# NVIC Register Definitions: IP-XACT component
VLNV meklort:<PROJECT>:NVIC Register Definitions:1.0

## Address spaces and blocks
NVIC.NVIC: base 0xE000E000, range , width , register

## Registers
Registers are 32-bit, read-write, no defined reset value unless marked. A register's access mark holds for its fields unless they carry their own. Offsets are from the block's base; lines under a group give offsets from that group; [hi:lo] are bit positions; {n}, {i} and the like mark numbered series; 'fields as' and 'values as' point back to an identical list; <NAME> marks a mode.

## NVIC.NVIC — Nested Vectored Interrupt Controller
Base 0xE000E000
0x04 Interrupt Control Type access not given — Read the Interrupt Controller Type Register to see the number of interrupt lines that the NVIC supports.
  [3:0] INTLINESNUM
    0=0 to 32; 1=33 to 64; 2=65 to 96
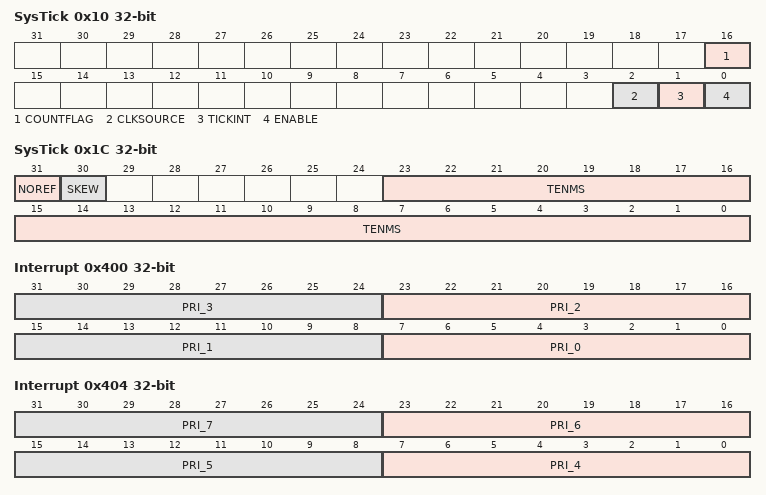
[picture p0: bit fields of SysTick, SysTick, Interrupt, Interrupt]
0x10 SysTick Control and Status — Use the SysTick Control and Status Register to enable the SysTick features.
  [16] COUNTFLAG — Returns 1 if timer counted to 0 since last time this was read. Clears on read by application of any part of the SysTick Control and Status Register. If read by the debugger using the DAP, this bit is cleared on read-only if the MasterType bit in the AHB-AP Control Register is set to 0. Otherwise, the COUNTFLAG bit is not changed by the debugger read.
  [2] CLKSOURCE — If no reference clock is provided, it is held at 1 and so gives the same time as the core clock. The core clock must be at least 2.5 times faster than the reference clock. If it is not, the count values are Unpredictable.
  [1] TICKINT — If set, counting down to 0 pends the SysTick handler.
  [0] ENABLE — It set, counter loads with the Reload value and then begins counting down. On reaching 0, it sets the COUNTFLAG to 1 and optionally pends the SysTick handler, based on TICKINT. It then loads the Reload value again, and begins counting.
0x14 SysTick Reload Value — Use the SysTick Reload Value Register to specify the start value to load into the current value register when the counter reaches 0. It can be any value between 1 and 0x00FFFFFF. A start value of 0 is possible, but has no effect because the SysTick interrupt and COUNTFLAG are activated when counting from 1 to 0.
  [23:0] RELOAD — Value to load into the SysTick Current Value Register when the counter reaches 0.
0x18 SysTick Current Value — Use the SysTick Current Value Register to find the current value in the register.
  [23:0] CURRENT — Current value at the time the register is accessed. No read-modify-write protection is provided, so change with care. This register is write-clear. Writing to it with any value clears the register to 0. Clearing this register also clears the COUNTFLAG bit of the SysTick Control and Status Register.
0x1C SysTick Calibration Value — Use the SysTick Calibration Value Register to enable software to scale to any required speed using divide and multiply.
  [31] NOREF — 1 = the reference clock is not provided.
  [30] SKEW — 1 = the calibration value is not exactly 10ms because of clock frequency. This could affect its suitability as a software real time clock.
  [23:0] TENMS — This value is the Reload value to use for 10ms timing. Depending on the value of SKEW, this might be exactly 10ms or might be the closest value. If this reads as 0, then the calibration value is not known. This is probably because the reference clock is an unknown input from the system or scalable dynamically.
0x100 Interrupt Set-Enable — Each bit in the register corresponds to one of 32 interrupts. Setting a bit in the Interrupt Set-Enable Register enables the corresponding interrupt. When the enable bit of a pending interrupt is set, the processor activates the interrupt based on its priority. When the enable bit is clear, asserting its interrupt signal pends the interrupt, but it is not possible to activate the interrupt, regardless of its priority. Therefore, a disabled interrupt can serve as a latched general-purpose I/O bit. You can read it and clear it without invoking an interrupt.
  [31:0] SETENA — Writing 0 to a SETENA bit has no effect. Reading the bit returns its current enable state. Reset clears the SETENA fields.
    0x100=H2B; 0x800=RX Packet Even (Port 0 or 2 received a packet.); 0x4000=SMBUS 0; 0x10000=SMBUS 1; 0x20000=RMU Egress (A packet was transmitted via the RMU); 0x100000=General Reset; 0x1000000=VMain (The Vmain port state has changed.); 0x2000000=Link State Even (Port 0 or 2 has had a link state event.); 0x4000000=Link State Odd (Port 1 or 3 has had a link state event.); 0x8000000=RX Packet Odd (Port 1 or 3 received a packet.)
0x180 Interrupt Clear-Enable — Each bit in the register corresponds to one of the 32 interrupts. Setting an Interrupt Clear-Enable Register bit disables the corresponding interrupt.
  [31:0] CLRENA — Writing 0 to a CLRENA bit has no effect. Reading the bit returns its current enable state.
    0x100=H2B; 0x800=RX Packet Even (Port 0 or 2 received a packet.); 0x4000=SMBUS 0; 0x10000=SMBUS 1; 0x20000=RMU Egress (A packet was transmitted via the RMU); 0x100000=General Reset; 0x1000000=VMain (The Vmain port state has changed.); 0x2000000=Link State Even (Port 0 or 2 has had a link state event.); 0x4000000=Link State Odd (Port 1 or 3 has had a link state event.); 0x8000000=RX Packet Odd (Port 1 or 3 received a packet.)
0x200 Interrupt Set-Pending — Each bit in the register corresponds to one of the 32 interrupts. Setting an Interrupt Set-Pending Register bit pends the corresponding interrupt.
  [31:0] SETPEND — Writing 0 to a SETPEND bit has no effect. Reading the bit returns its current state.
    0x100=H2B; 0x800=RX Packet Even (Port 0 or 2 received a packet.); 0x4000=SMBUS 0; 0x10000=SMBUS 1; 0x20000=RMU Egress (A packet was transmitted via the RMU); 0x100000=General Reset; 0x1000000=VMain (The Vmain port state has changed.); 0x2000000=Link State Even (Port 0 or 2 has had a link state event.); 0x4000000=Link State Odd (Port 1 or 3 has had a link state event.); 0x8000000=RX Packet Odd (Port 1 or 3 received a packet.)
0x280 Interrupt Clear-Pending — Each bit in the register corresponds to one of the 32 interrupts. Setting an Interrupt Clear-Pending Register bit puts the corresponding pending interrupt in the inactive state.
  [31:0] CLRPEND — Writing 0 to a CLRPEND bit has no effect. Reading the bit returns its current state.
    0x100=H2B; 0x800=RX Packet Even (Port 0 or 2 received a packet.); 0x4000=SMBUS 0; 0x10000=SMBUS 1; 0x20000=RMU Egress (A packet was transmitted via the RMU); 0x100000=General Reset; 0x1000000=VMain (The Vmain port state has changed.); 0x2000000=Link State Even (Port 0 or 2 has had a link state event.); 0x4000000=Link State Odd (Port 1 or 3 has had a link state event.); 0x8000000=RX Packet Odd (Port 1 or 3 received a packet.)
0x300 Active Bit — Read the Active Bit Register to determine which interrupts are active. Each flag in the register corresponds to one of the 32 interrupts.
  [31:0] ACTIVE — Interrupt active flags.
0x400 Interrupt Priority 0 — Use the Interrupt Priority Registers to assign a priority from 0 to 255 to each of the available interrupts. 0 is the highest priority, and 255 is the lowest.
  [8n+7:8n] PRI_{n} (n=0..3) — Priority of Interrupt {n}.
0x404 Interrupt Priority 1 — Use the Interrupt Priority Registers to assign a priority from 0 to 255 to each of the available interrupts. 0 is the highest priority, and 255 is the lowest.
  [8n-25:8n-32] PRI_{n} (n=4..7) — Priority of Interrupt {n}.
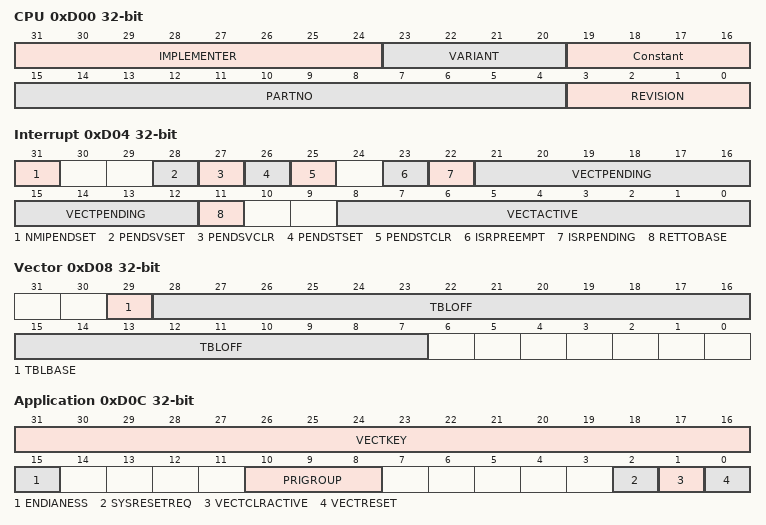
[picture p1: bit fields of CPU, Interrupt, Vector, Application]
0xD00 CPU ID — Read the CPU ID Base Register to determine: the ID number of the processor core, the version number of the processor core, the implementation details of the processor core.
  [31:24] IMPLEMENTER — Implementer code. ARM is 0x41.
  [23:20] VARIANT — Implementation defined variant number.
  [19:16] Constant — Priority of Interrupt 6.
  [15:4] PARTNO — Reads as 0xF
  [3:0] REVISION — Implementation defined revision number.
0xD04 Interrupt Control State access per field — Use the Interrupt Control State Register to: set a pending Non-Maskable Interrupt (NMI), set or clear a pending SVC, set or clear a pending SysTick, check for pending exceptions, check the vector number of the highest priority pended exception, check the vector number of the active exception.
  [31] NMIPENDSET rw — NMIPENDSET pends and activates an NMI. Because NMI is the highest-priority interrupt, it takes effect as soon as it registers.
  [28] PENDSVSET rw — Set pending pendSV bit.
  [27] PENDSVCLR wo — Clear pending pendSV bit.
  [26] PENDSTSET rw — Set a pending SysTick bit.
  [25] PENDSTCLR wo — Clear pending SysTick bit.
  [23] ISRPREEMPT ro — You must only use this at debug time. It indicates that a pending interrupt becomes active in the next running cycle. If C_MASKINTS is clear in the Debug Halting Control and Status Register, the interrupt is serviced.
  [22] ISRPENDING ro — Interrupt pending flag. Excludes NMI and Faults.
  [21:12] VECTPENDING ro — Pending ISR number field. VECTPENDING contains the interrupt number of the highest priority pending ISR.
  [11] RETTOBASE ro — This bit is 1 when the set of all active exceptions minus the IPSR_current_exception yields the empty set.
  [8:0] VECTACTIVE ro — Active ISR number field. VECTACTIVE contains the interrupt number of the currently running ISR, including NMI and Hard Fault. A shared handler can use VECTACTIVE to determine which interrupt invoked it. You can subtract 16 from the VECTACTIVE field to index into the Interrupt Clear/Set Enable, Interrupt Clear Pending/SetPending and Interrupt Priority Registers. INTISR[0] has vector number 16.
0xD08 Vector Table Offset — Use the Vector Table Offset Register to determine: if the vector table is in RAM or code memory, the vector table offset.
  [29] TBLBASE — Table base is in Code (0) or RAM (1).
  [28:7] TBLOFF — Vector table base offset field. Contains the offset of the table base from the bottom of the SRAM or CODE space.
0xD0C Application Interrupt and Reset Control — the Application Interrupt and Reset Control Register to: determine data endianness, clear all active state information for debug or to recover from a hard failure, execute a system reset, alter the priority grouping position (binary point).
  [31:16] VECTKEY — Register key. Writing to this register requires 0x5FA in the VECTKEY field. Otherwise the write value is ignored. Reads as 0xFA05.
  [15] ENDIANESS — Data endianness bit: 1 = big endian.
  [10:8] PRIGROUP — PRIGROUP field is a binary point position indicator for creating subpriorities for exceptions that share the same pre-emption level. It divides the PRI_n field in the Interrupt Priority Register into a pre-emption level and a subpriority level. The binary point is a left-of value. This means that the PRIGROUP value represents a point starting at the left of the Least Significant Bit (LSB). This is bit [0] of 7:0. The lowest value might not be 0 depending on the number of bits allocated for priorities, and implementation choices.
  [2] SYSRESETREQ — Causes a signal to be asserted to the outer system that indicates a reset is requested. Intended to force a large system reset of all major components except for debug. Setting this bit does not prevent Halting Debug from running.
  [1] VECTCLRACTIVE — Clear active vector bit.
  [0] VECTRESET — System Reset bit. Resets the system, with the exception of debug components.
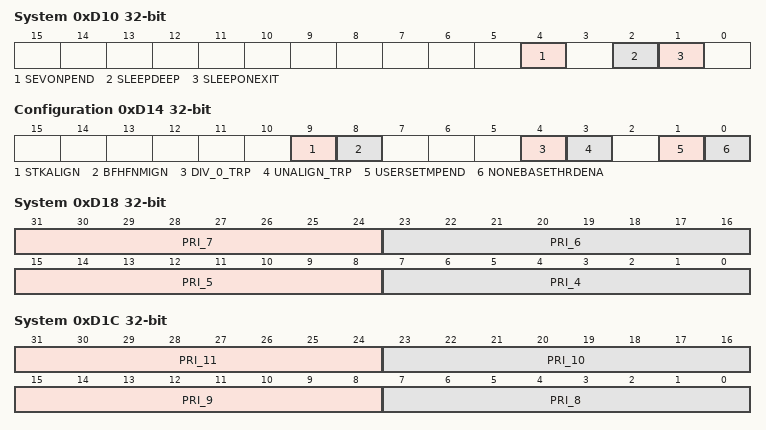
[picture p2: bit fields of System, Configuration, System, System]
0xD10 System Control — Use the System Control Register for power-management functions: signal to the system when the processor can enter a low power state, control how the processor enters and exits low power states.
  [4] SEVONPEND — When enabled, this causes WFE to wake up when an interrupt moves from inactive to pended. Otherwise, WFE only wakes up from an event signal, external and SEV instruction generated. The event input, RXEV, is registered even when not waiting for an event, and so effects the next WFE.
  [2] SLEEPDEEP — 1 = indicates to the system that Cortex-M3 clock can be stopped. Setting this bit causes the SLEEPDEEP port to be asserted when the processor can be stopped.
  [1] SLEEPONEXIT — Sleep on exit when returning from Handler mode to Thread mode: 1 = sleep on ISR exit.
0xD14 Configuration Control — Use the Configuration Control Register to: enable NMI, Hard Fault and FAULTMASK to ignore bus fault, trap divide by zero, and unaligned accesses, enable user access to the Software Trigger Exception Register, control entry to Thread Mode.
  [9] STKALIGN — 1 = on exception entry, the SP used prior to the exception is adjusted to be 8-byte aligned and the context to restore it is saved. The SP is restored on the associated exception return. 0 = only 4-byte alignment is guaranteed for the SP used prior to the exception on exception entry.
  [8] BFHFNMIGN — When enabled, this causes handlers running at priority -1 and -2 (Hard Fault, NMI, and FAULTMASK escalated handlers) to ignore Data Bus faults caused by load and store instructions. When disabled, these bus faults cause a lock-up. You must only use this enable with extreme caution. All data bus faults are ignored – you must only use it when the handler and its data are in absolutely safe memory. Its normal use is to probe system devices and bridges to detect control path problems and fix them.
  [4] DIV_0_TRP — Trap on Divide by 0. This enables faulting/halting when an attempt is made to divide by 0. The relevant Usage Fault Status Register bit is DIVBYZERO, see Usage Fault Status Register.
  [3] UNALIGN_TRP — Trap for unaligned access. This enables faulting/halting on any unaligned half or full word access. Unaligned load-store multiples always fault. The relevant Usage Fault Status Register bit is UNALIGNED, see Usage Fault Status Register.
  [1] USERSETMPEND — If written as 1, enables user code to write the Software Trigger Interrupt register to trigger (pend) a Main exception, which is one associated with the Main stack pointer.
  [0] NONEBASETHRDENA — When 0, default, It is only possible to enter Thread mode when returning from the last exception. When set to 1, Thread mode can be entered from any level in Handler mode by controlled return value.
0xD18 System Handler Priority 4 — System handlers are a special class of exception handler that can have their priority set to any of the priority levels. Most can be masked on (enabled) or off (disabled). When disabled, the fault is always treated as a Hard Fault.
  [31:24] PRI_7 — Reserved.
  [23:16] PRI_6 — Priority of Usage Fault.
  [15:8] PRI_5 — Priority of Bus Fault.
  [7:0] PRI_4 — Priority of Mem Manage.
0xD1C System Handler Priority 8 — System handlers are a special class of exception handler that can have their priority set to any of the priority levels. Most can be masked on (enabled) or off (disabled). When disabled, the fault is always treated as a Hard Fault.
  [31:24] PRI_11 — Priority of SVCall.
  [23:16] PRI_10 — Reserved.
  [15:8] PRI_9 — Reserved.
  [7:0] PRI_8 — Reserved.
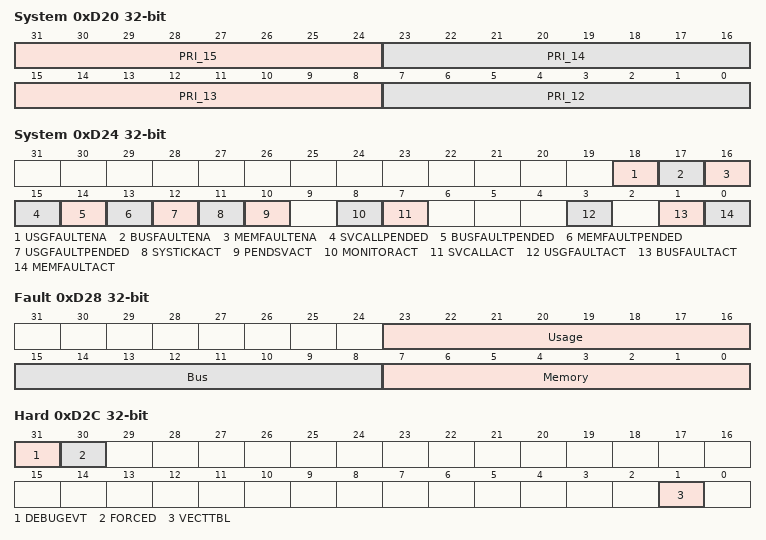
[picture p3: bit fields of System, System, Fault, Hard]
0xD20 System Handler Priority 12 — System handlers are a special class of exception handler that can have their priority set to any of the priority levels. Most can be masked on (enabled) or off (disabled). When disabled, the fault is always treated as a Hard Fault.
  [31:24] PRI_15 — Priority of SysTick.
  [23:16] PRI_14 — Priority of PendSV.
  [15:8] PRI_13 — Reserved.
  [7:0] PRI_12 — Priority of Debug Monitor.
0xD24 System Handler Control and State — Use the System Handler Control and State Register to: enable or disable the system handlers, determine the pending status of bus fault, mem manage fault, and SVC, determine the active status of the system handlers.
  [18] USGFAULTENA — Set to 0 to disable, else 1 for enabled.
  [17] BUSFAULTENA — Set to 0 to disable, else 1 for enabled.
  [16] MEMFAULTENA — Set to 0 to disable, else 1 for enabled.
  [15] SVCALLPENDED — Reads as 1 if SVCall is pended.
  [14] BUSFAULTPENDED — Reads as 1 if BusFault is pended.
  [13] MEMFAULTPENDED — Reads as 1 if MemManage is pended.
  [12] USGFAULTPENDED — Read as 1 if usage fault is pended.
  [11] SYSTICKACT — Reads as 1 if SysTick is active.
  [10] PENDSVACT — Reads as 1 if PendSV is active.
  [8] MONITORACT — Reads as 1 if the Monitor is active.
  [7] SVCALLACT — Reads as 1 if SVCall is active.
  [3] USGFAULTACT — Reads as 1 if UsageFault is active.
  [1] BUSFAULTACT — Reads as 1 if BusFault is active.
  [0] MEMFAULTACT — Reads as 1 if MemManage is active.
0xD28 Fault Status — The flags in these registers indicate the causes of local faults. Multiple flags can be set if more than one fault occurs. These register are read/write-clear. This means that they can be read normally, but writing a 1 to any bit clears that bit.
  [23:16] Usage Fault Status — The flags in the Bus Fault Status Register indicate the cause of usage faults.
  [15:8] Bus Fault Status — The flags in the Bus Fault Status Register indicate the cause of bus access faults.
  [7:0] Memory Manage Fault Status — The flags in the Memory Manage Fault Status Register indicate the cause of memory access faults.
0xD2C Hard Fault Status — Use the Hard Fault Status Register (HFSR) to obtain information about events that activate the Hard Fault handler.
  [31] DEBUGEVT — This bit is set if there is a fault related to debug. This is only possible when halting debug is not enabled. For monitor enabled debug, it only happens for BKPT when the current priority is higher than the monitor. When both halting and monitor debug are disabled, it only happens for debug events that are not ignored (minimally, BKPT). The Debug Fault Status Register is updated.
  [30] FORCED — Hard Fault activated because a Configurable Fault was received and cannot activate because of priority or because the Configurable Fault is disabled. The Hard Fault handler then has to read the other fault status registers to determine cause.
  [1] VECTTBL — This bit is set if there is a fault because of vector table read on exception processing (Bus Fault). This case is always a Hard Fault. The return PC points to the pre-empted instruction.
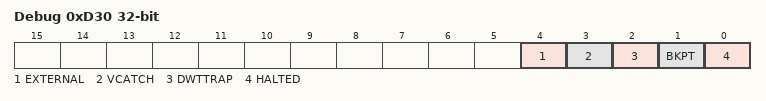
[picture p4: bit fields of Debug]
0xD30 Debug Fault Status — Use the Debug Fault Status Register to monitor: external debug requests, vector catches, data watchpoint match, BKPT instruction execution, halt requests.
  [4] EXTERNAL — External debug request flag.
  [3] VCATCH — Vector catch flag.
  [2] DWTTRAP — Data Watchpoint and Trace (DWT) flag.
  [1] BKPT — The BKPT flag is set by a BKPT instruction in flash patch code, and also by normal code. Return PC points to breakpoint containing instruction.
  [0] HALTED — 1 = halt requested by NVIC, including step. The processor is halted on the next instruction.
0xD34 Memory Manage Fault Address — Use the Memory Manage Fault Address Register to read the address of the location that caused a Memory Manage Fault.
  [31:0] ADDRESS — Mem Manage fault address field. ADDRESS is the data address of a faulted load or store attempt. When an unaligned access faults, the address is the actual address that faulted. Because an access can be split into multiple parts, each aligned, this address can be any offset in the range of the requested size. Flags in the Memory Manage Fault Status Register indicate the cause of the fault.
0xD38 Bus Fault Address — Use the Bus Fault Address Register to read the address of the location that generated a Bus Fault.
  [31:0] ADDRESS — Bus fault address field. ADDRESS is the data address of a faulted load or store attempt. When an unaligned access faults, the address is the address requested by the instruction, even if that is not the address that faulted. Flags in the Bus Fault Status Register indicate the cause of the fault.
0xD3C Auxiliary Fault Address — Use the Auxiliary Fault Status Register (AFSR) to determine additional system fault information to software. The AFSR flags map directly onto the AUXFAULT inputs of the processor, and a single-cycle high level on an external pin causes the corresponding AFSR bit to become latched as one. The bit can only be cleared by writing a one to the corresponding AFSR bit. When an AFSR bit is written or latched as one, an exception does not occur. If you require an exception, you must use an interrupt.
  [31:0] IMPDEF — Implementation defined. The bits map directly onto the signal assignment to the AUXFAULT inputs.
0xF00 Software Trigger Interrupt — Use the Software Trigger Interrupt Register to pend an interrupt to trigger.
  [7:0] INTID — Interrupt ID field. Writing a value to the INTID field is the same as manually pending an interrupt by setting the corresponding interrupt bit in an Interrupt Set Pending Register.
